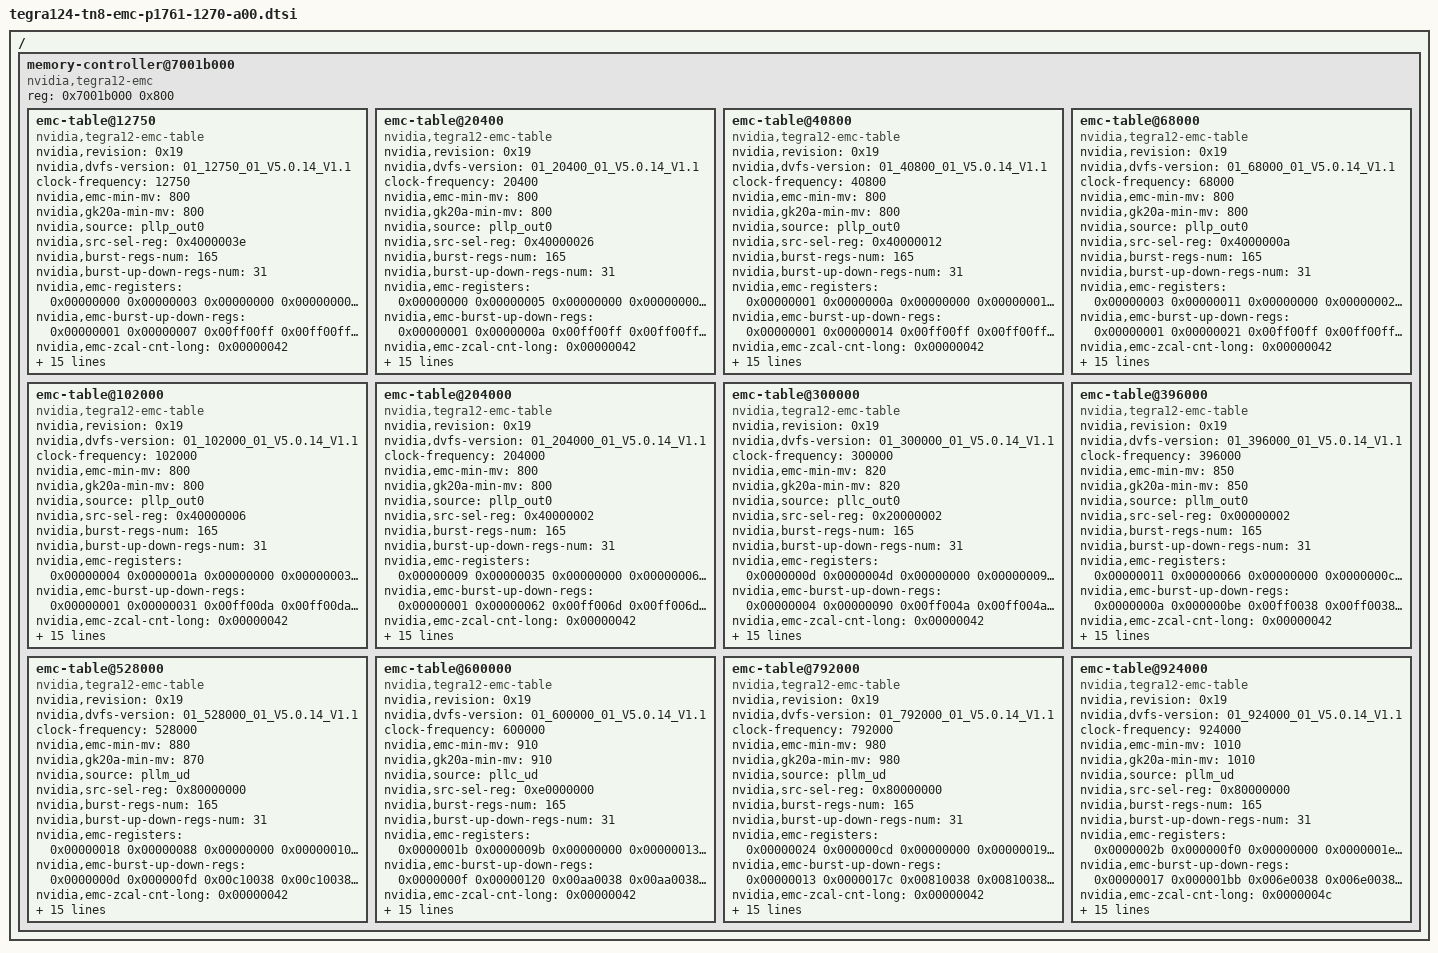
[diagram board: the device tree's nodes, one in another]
/ {
memory-controller@7001b000 {
		compatible = "nvidia,tegra12-emc";
		reg = <0x7001b000 0x800>;
		#address-cells = <1>;
		#size-cells = <0>;
		emc-table@12750 {
			compatible = "nvidia,tegra12-emc-table";
			nvidia,revision = <0x19>;
			nvidia,dvfs-version = "01_12750_01_V5.0.14_V1.1";
			clock-frequency = <12750>;
			nvidia,emc-min-mv = <800>;
			nvidia,gk20a-min-mv = <800>;
			nvidia,source = "pllp_out0";
			nvidia,src-sel-reg = <0x4000003e>;
			nvidia,burst-regs-num = <165>;
			nvidia,burst-up-down-regs-num = <31>;
			nvidia,emc-registers = <
				0x00000000
				0x00000003
				0x00000000
				0x00000000
				0x00000000
				0x00000004
				0x0000000a
				0x00000003
				0x0000000b
				0x00000000
				0x00000000
				0x00000003
				0x00000003
				0x00000000
				0x00000006
				0x00000006
				0x00000006
				0x00000002
				0x00000000
				0x00000005
				0x00000005
				0x00010000
				0x00000003
				0x00000000
				0x00000000
				0x00000000
				0x00000000
				0x00000004
				0x0000000c
				0x0000000d
				0x0000000f
				0x00000060
				0x00000000
				0x00000018
				0x00000002
				0x00000002
				0x00000001
				0x00000000
				0x00000007
				0x0000000f
				0x00000005
				0x00000005
				0x00000004
				0x00000005
				0x00000004
				0x00000000
				0x00000000
				0x00000005
				0x00000005
				0x00000064
				0x00000000
				0x00000000
				0x00000000
				0x1069a298
				0x002c00a0
				0x00008000
				0x00064000
				0x00064000
				0x00064000
				0x00064000
				0x00064000
				0x00064000
				0x00064000
				0x00064000
				0x00064000
				0x00064000
				0x00064000
				0x00064000
				0x00064000
				0x00064000
				0x00064000
				0x00064000
				0x00000000
				0x00000000
				0x00000000
				0x00000000
				0x00000000
				0x00000000
				0x00000000
				0x00000000
				0x00000000
				0x00000000
				0x00014000
				0x00000000
				0x00000000
				0x00014000
				0x00000000
				0x00000000
				0x00000000
				0x00000000
				0x00000000
				0x00000000
				0x00000000
				0x00000000
				0x00000000
				0x00000000
				0x00000000
				0x00000000
				0x00000000
				0x00000000
				0x00000000
				0x00000000
				0x00000000
				0x00000000
				0x00000000
				0x00000000
				0x00000000
				0x00000000
				0x00000000
				0x00000000
				0x000fc000
				0x000fc000
				0x000fc000
				0x000fc000
				0x0000fc00
				0x0000fc00
				0x0000fc00
				0x0000fc00
				0x10000280
				0x00000000
				0x00111111
				0x0130b118
				0x00000000
				0x00000000
				0x77ffc081
				0x00000909
				0x81f1f108
				0x07070004
				0x0000003f
				0x016eeeee
				0x51451400
				0x00514514
				0x00514514
				0x51451400
				0x0000003f
				0x00000007
				0x00000000
				0x00000000
				0x00000042
				0x000e000e
				0x000e000e
				0x00000000
				0x00000003
				0x0000f2f3
				0x800001c5
				0x0000000a
				0x40040001
				0x8000000a
				0x00000001
				0x00000001
				0x00000002
				0x00000000
				0x00000002
				0x00000001
				0x00000002
				0x00000008
				0x00000003
				0x00000002
				0x00000003
				0x00000006
				0x06030203
				0x000a0402
				0x77e30303
				0x70000f03
				0x001f0000
			>;
			nvidia,emc-burst-up-down-regs = <
			0x00000001
			0x00000007
			0x00ff00ff
			0x00ff00ff
			0x00ff00ff
			0x00ff00ff
			0x00ff00ff
			0x00ff00ff
			0x00ff00ff
			0x00ff0049
			0x00ff0080
			0x00ff0004
			0x00ff0004
			0x000800ff
			0x000000ff
			0x00ff0004
			0x00ff00ff
			0x00ff00ff
			0x00ff0024
			0x00ff00ff
			0x000000ff
			0x000000ff
			0x00ff00ff
			0x000000ff
			0x00ff00ff
			0x00ff00ff
			0x00ff00ff
			0x00ff00ff
			0x00ff00ff
			0x00ff00ff
			0x00ff00ff
			>;
			nvidia,emc-zcal-cnt-long = <0x00000042>;
			nvidia,emc-acal-interval = <0x001fffff>;
			nvidia,emc-ctt-term_ctrl = <0x00000802>;
			nvidia,emc-cfg = <0x73240000>;
			nvidia,emc-cfg-2 = <0x000008c5>;
			nvidia,emc-sel-dpd-ctrl = <0x00040128>;
			nvidia,emc-cfg-dig-dll = <0x002c0068>;
			nvidia,emc-bgbias-ctl0 = <0x00000008>;
			nvidia,emc-auto-cal-config2 = <0x00000000>;
			nvidia,emc-auto-cal-config3 = <0x00000000>;
			nvidia,emc-auto-cal-config = <0xa1430000>;
			nvidia,emc-mode-0 = <0x80001221>;
			nvidia,emc-mode-1 = <0x80100003>;
			nvidia,emc-mode-2 = <0x80200008>;
			nvidia,emc-mode-4 = <0x00000000>;
			nvidia,emc-clock-latency-change = <57820>;
		};
		emc-table@20400 {
			compatible = "nvidia,tegra12-emc-table";
			nvidia,revision = <0x19>;
			nvidia,dvfs-version = "01_20400_01_V5.0.14_V1.1";
			clock-frequency = <20400>;
			nvidia,emc-min-mv = <800>;
			nvidia,gk20a-min-mv = <800>;
			nvidia,source = "pllp_out0";
			nvidia,src-sel-reg = <0x40000026>;
			nvidia,burst-regs-num = <165>;
			nvidia,burst-up-down-regs-num = <31>;
			nvidia,emc-registers = <
				0x00000000
				0x00000005
				0x00000000
				0x00000000
				0x00000000
				0x00000004
				0x0000000a
				0x00000003
				0x0000000b
				0x00000000
				0x00000000
				0x00000003
				0x00000003
				0x00000000
				0x00000006
				0x00000006
				0x00000006
				0x00000002
				0x00000000
				0x00000005
				0x00000005
				0x00010000
				0x00000003
				0x00000000
				0x00000000
				0x00000000
				0x00000000
				0x00000004
				0x0000000c
				0x0000000d
				0x0000000f
				0x0000009a
				0x00000000
				0x00000026
				0x00000002
				0x00000002
				0x00000001
				0x00000000
				0x00000007
				0x0000000f
				0x00000006
				0x00000006
				0x00000004
				0x00000005
				0x00000004
				0x00000000
				0x00000000
				0x00000005
				0x00000005
				0x000000a0
				0x00000000
				0x00000000
				0x00000000
				0x1069a298
				0x002c00a0
				0x00008000
				0x00064000
				0x00064000
				0x00064000
				0x00064000
				0x00064000
				0x00064000
				0x00064000
				0x00064000
				0x00064000
				0x00064000
				0x00064000
				0x00064000
				0x00064000
				0x00064000
				0x00064000
				0x00064000
				0x00000000
				0x00000000
				0x00000000
				0x00000000
				0x00000000
				0x00000000
				0x00000000
				0x00000000
				0x00000000
				0x00000000
				0x00014000
				0x00000000
				0x00000000
				0x00014000
				0x00000000
				0x00000000
				0x00000000
				0x00000000
				0x00000000
				0x00000000
				0x00000000
				0x00000000
				0x00000000
				0x00000000
				0x00000000
				0x00000000
				0x00000000
				0x00000000
				0x00000000
				0x00000000
				0x00000000
				0x00000000
				0x00000000
				0x00000000
				0x00000000
				0x00000000
				0x00000000
				0x00000000
				0x000fc000
				0x000fc000
				0x000fc000
				0x000fc000
				0x0000fc00
				0x0000fc00
				0x0000fc00
				0x0000fc00
				0x10000280
				0x00000000
				0x00111111
				0x0130b118
				0x00000000
				0x00000000
				0x77ffc081
				0x00000909
				0x81f1f108
				0x07070004
				0x0000003f
				0x016eeeee
				0x51451400
				0x00514514
				0x00514514
				0x51451400
				0x0000003f
				0x0000000b
				0x00000000
				0x00000000
				0x00000042
				0x000e000e
				0x000e000e
				0x00000000
				0x00000003
				0x0000f2f3
				0x8000023a
				0x0000000a
				0x40020001
				0x80000012
				0x00000001
				0x00000001
				0x00000002
				0x00000000
				0x00000002
				0x00000001
				0x00000002
				0x00000008
				0x00000003
				0x00000002
				0x00000003
				0x00000006
				0x06030203
				0x000a0402
				0x76230303
				0x70000f03
				0x001f0000
			>;
			nvidia,emc-burst-up-down-regs = <
			0x00000001
			0x0000000a
			0x00ff00ff
			0x00ff00ff
			0x00ff00ff
			0x00ff00ff
			0x00ff00ff
			0x00ff00ff
			0x00ff00ff
			0x00ff0049
			0x00ff0080
			0x00ff0004
			0x00ff0004
			0x000800ff
			0x000000ff
			0x00ff0004
			0x00ff00ff
			0x00ff00ff
			0x00ff0024
			0x00ff00ff
			0x000000ff
			0x000000ff
			0x00ff00ff
			0x000000ff
			0x00ff00ff
			0x00ff00ff
			0x00ff00ff
			0x00ff00ff
			0x00ff00ff
			0x00ff00ff
			0x00ff00ff
			>;
			nvidia,emc-zcal-cnt-long = <0x00000042>;
			nvidia,emc-acal-interval = <0x001fffff>;
			nvidia,emc-ctt-term_ctrl = <0x00000802>;
			nvidia,emc-cfg = <0x73240000>;
			nvidia,emc-cfg-2 = <0x000008c5>;
			nvidia,emc-sel-dpd-ctrl = <0x00040128>;
			nvidia,emc-cfg-dig-dll = <0x002c0068>;
			nvidia,emc-bgbias-ctl0 = <0x00000008>;
			nvidia,emc-auto-cal-config2 = <0x00000000>;
			nvidia,emc-auto-cal-config3 = <0x00000000>;
			nvidia,emc-auto-cal-config = <0xa1430000>;
			nvidia,emc-mode-0 = <0x80001221>;
			nvidia,emc-mode-1 = <0x80100003>;
			nvidia,emc-mode-2 = <0x80200008>;
			nvidia,emc-mode-4 = <0x00000000>;
			nvidia,emc-clock-latency-change = <35610>;
		};
		emc-table@40800 {
			compatible = "nvidia,tegra12-emc-table";
			nvidia,revision = <0x19>;
			nvidia,dvfs-version = "01_40800_01_V5.0.14_V1.1";
			clock-frequency = <40800>;
			nvidia,emc-min-mv = <800>;
			nvidia,gk20a-min-mv = <800>;
			nvidia,source = "pllp_out0";
			nvidia,src-sel-reg = <0x40000012>;
			nvidia,burst-regs-num = <165>;
			nvidia,burst-up-down-regs-num = <31>;
			nvidia,emc-registers = <
				0x00000001
				0x0000000a
				0x00000000
				0x00000001
				0x00000000
				0x00000004
				0x0000000a
				0x00000003
				0x0000000b
				0x00000000
				0x00000000
				0x00000003
				0x00000003
				0x00000000
				0x00000006
				0x00000006
				0x00000006
				0x00000002
				0x00000000
				0x00000005
				0x00000005
				0x00010000
				0x00000003
				0x00000000
				0x00000000
				0x00000000
				0x00000000
				0x00000004
				0x0000000c
				0x0000000d
				0x0000000f
				0x00000134
				0x00000000
				0x0000004d
				0x00000002
				0x00000002
				0x00000001
				0x00000000
				0x00000008
				0x0000000f
				0x0000000c
				0x0000000c
				0x00000004
				0x00000005
				0x00000004
				0x00000000
				0x00000000
				0x00000005
				0x00000005
				0x0000013f
				0x00000000
				0x00000000
				0x00000000
				0x1069a298
				0x002c00a0
				0x00008000
				0x00064000
				0x00064000
				0x00064000
				0x00064000
				0x00064000
				0x00064000
				0x00064000
				0x00064000
				0x00064000
				0x00064000
				0x00064000
				0x00064000
				0x00064000
				0x00064000
				0x00064000
				0x00064000
				0x00000000
				0x00000000
				0x00000000
				0x00000000
				0x00000000
				0x00000000
				0x00000000
				0x00000000
				0x00000000
				0x00000000
				0x00014000
				0x00000000
				0x00000000
				0x00014000
				0x00000000
				0x00000000
				0x00000000
				0x00000000
				0x00000000
				0x00000000
				0x00000000
				0x00000000
				0x00000000
				0x00000000
				0x00000000
				0x00000000
				0x00000000
				0x00000000
				0x00000000
				0x00000000
				0x00000000
				0x00000000
				0x00000000
				0x00000000
				0x00000000
				0x00000000
				0x00000000
				0x00000000
				0x000fc000
				0x000fc000
				0x000fc000
				0x000fc000
				0x0000fc00
				0x0000fc00
				0x0000fc00
				0x0000fc00
				0x10000280
				0x00000000
				0x00111111
				0x0130b118
				0x00000000
				0x00000000
				0x77ffc081
				0x00000909
				0x81f1f108
				0x07070004
				0x0000003f
				0x016eeeee
				0x51451400
				0x00514514
				0x00514514
				0x51451400
				0x0000003f
				0x00000015
				0x00000000
				0x00000000
				0x00000042
				0x000e000e
				0x000e000e
				0x00000000
				0x00000003
				0x0000f2f3
				0x80000370
				0x0000000a
				0xa0000001
				0x80000017
				0x00000001
				0x00000001
				0x00000002
				0x00000000
				0x00000002
				0x00000001
				0x00000002
				0x00000008
				0x00000003
				0x00000002
				0x00000003
				0x00000006
				0x06030203
				0x000a0402
				0x74a30303
				0x70000f03
				0x001f0000
			>;
			nvidia,emc-burst-up-down-regs = <
			0x00000001
			0x00000014
			0x00ff00ff
			0x00ff00ff
			0x00ff00ff
			0x00ff00ff
			0x00ff00ff
			0x00ff00ff
			0x00ff00ff
			0x00ff0049
			0x00ff0080
			0x00ff0004
			0x00ff0004
			0x000800ff
			0x000000ff
			0x00ff0004
			0x00ff00ff
			0x00ff00ff
			0x00ff0024
			0x00ff00ff
			0x000000ff
			0x000000ff
			0x00ff00ff
			0x000000ff
			0x00ff00ff
			0x00ff00ff
			0x00ff00ff
			0x00ff00ff
			0x00ff00ff
			0x00ff00ff
			0x00ff00ff
			>;
			nvidia,emc-zcal-cnt-long = <0x00000042>;
			nvidia,emc-acal-interval = <0x001fffff>;
			nvidia,emc-ctt-term_ctrl = <0x00000802>;
			nvidia,emc-cfg = <0x73240000>;
			nvidia,emc-cfg-2 = <0x000008c5>;
			nvidia,emc-sel-dpd-ctrl = <0x00040128>;
			nvidia,emc-cfg-dig-dll = <0x002c0068>;
			nvidia,emc-bgbias-ctl0 = <0x00000008>;
			nvidia,emc-auto-cal-config2 = <0x00000000>;
			nvidia,emc-auto-cal-config3 = <0x00000000>;
			nvidia,emc-auto-cal-config = <0xa1430000>;
			nvidia,emc-mode-0 = <0x80001221>;
			nvidia,emc-mode-1 = <0x80100003>;
			nvidia,emc-mode-2 = <0x80200008>;
			nvidia,emc-mode-4 = <0x00000000>;
			nvidia,emc-clock-latency-change = <20850>;
		};
		emc-table@68000 {
			compatible = "nvidia,tegra12-emc-table";
			nvidia,revision = <0x19>;
			nvidia,dvfs-version = "01_68000_01_V5.0.14_V1.1";
			clock-frequency = <68000>;
			nvidia,emc-min-mv = <800>;
			nvidia,gk20a-min-mv = <800>;
			nvidia,source = "pllp_out0";
			nvidia,src-sel-reg = <0x4000000a>;
			nvidia,burst-regs-num = <165>;
			nvidia,burst-up-down-regs-num = <31>;
			nvidia,emc-registers = <
				0x00000003
				0x00000011
				0x00000000
				0x00000002
				0x00000000
				0x00000004
				0x0000000a
				0x00000003
				0x0000000b
				0x00000000
				0x00000000
				0x00000003
				0x00000003
				0x00000000
				0x00000006
				0x00000006
				0x00000006
				0x00000002
				0x00000000
				0x00000005
				0x00000005
				0x00010000
				0x00000003
				0x00000000
				0x00000000
				0x00000000
				0x00000000
				0x00000004
				0x0000000c
				0x0000000d
				0x0000000f
				0x00000202
				0x00000000
				0x00000080
				0x00000002
				0x00000002
				0x00000001
				0x00000000
				0x0000000f
				0x0000000f
				0x00000013
				0x00000013
				0x00000004
				0x00000005
				0x00000004
				0x00000001
				0x00000000
				0x00000005
				0x00000005
				0x00000213
				0x00000000
				0x00000000
				0x00000000
				0x1069a298
				0x002c00a0
				0x00008000
				0x00064000
				0x00064000
				0x00064000
				0x00064000
				0x00064000
				0x00064000
				0x00064000
				0x00064000
				0x00064000
				0x00064000
				0x00064000
				0x00064000
				0x00064000
				0x00064000
				0x00064000
				0x00064000
				0x00000000
				0x00000000
				0x00000000
				0x00000000
				0x00000000
				0x00000000
				0x00000000
				0x00000000
				0x00000000
				0x00000000
				0x00014000
				0x00000000
				0x00000000
				0x00014000
				0x00000000
				0x00000000
				0x00000000
				0x00000000
				0x00000000
				0x00000000
				0x00000000
				0x00000000
				0x00000000
				0x00000000
				0x00000000
				0x00000000
				0x00000000
				0x00000000
				0x00000000
				0x00000000
				0x00000000
				0x00000000
				0x00000000
				0x00000000
				0x00000000
				0x00000000
				0x00000000
				0x00000000
				0x000fc000
				0x000fc000
				0x000fc000
				0x000fc000
				0x0000fc00
				0x0000fc00
				0x0000fc00
				0x0000fc00
				0x10000280
				0x00000000
				0x00111111
				0x0130b118
				0x00000000
				0x00000000
				0x77ffc081
				0x00000909
				0x81f1f108
				0x07070004
				0x0000003f
				0x016eeeee
				0x51451400
				0x00514514
				0x00514514
				0x51451400
				0x0000003f
				0x00000022
				0x00000000
				0x00000000
				0x00000042
				0x000e000e
				0x000e000e
				0x00000000
				0x00000003
				0x0000f2f3
				0x8000050e
				0x0000000a
				0x00000001
				0x8000001e
				0x00000001
				0x00000001
				0x00000002
				0x00000000
				0x00000002
				0x00000001
				0x00000002
				0x00000008
				0x00000003
				0x00000002
				0x00000003
				0x00000006
				0x06030203
				0x000a0402
				0x74230403
				0x70000f03
				0x001f0000
			>;
			nvidia,emc-burst-up-down-regs = <
			0x00000001
			0x00000021
			0x00ff00ff
			0x00ff00ff
			0x00ff00b0
			0x00ff00ff
			0x00ff00ec
			0x00ff00ff
			0x00ff00ec
			0x00e90049
			0x00ff0080
			0x00ff0004
			0x00ff0004
			0x000800ff
			0x000000ff
			0x00ff0004
			0x00ff00ff
			0x00ff00a3
			0x00ff0024
			0x00ff00ff
			0x000000ff
			0x000000ef
			0x00ff00ff
			0x000000ef
			0x00ff00ff
			0x00ff00ff
			0x00ee00ef
			0x00ff00ff
			0x00ff00ff
			0x00ff00ff
			0x00ff00ff
			>;
			nvidia,emc-zcal-cnt-long = <0x00000042>;
			nvidia,emc-acal-interval = <0x001fffff>;
			nvidia,emc-ctt-term_ctrl = <0x00000802>;
			nvidia,emc-cfg = <0x73240000>;
			nvidia,emc-cfg-2 = <0x000008c5>;
			nvidia,emc-sel-dpd-ctrl = <0x00040128>;
			nvidia,emc-cfg-dig-dll = <0x002c0068>;
			nvidia,emc-bgbias-ctl0 = <0x00000008>;
			nvidia,emc-auto-cal-config2 = <0x00000000>;
			nvidia,emc-auto-cal-config3 = <0x00000000>;
			nvidia,emc-auto-cal-config = <0xa1430000>;
			nvidia,emc-mode-0 = <0x80001221>;
			nvidia,emc-mode-1 = <0x80100003>;
			nvidia,emc-mode-2 = <0x80200008>;
			nvidia,emc-mode-4 = <0x00000000>;
			nvidia,emc-clock-latency-change = <10720>;
		};
		emc-table@102000 {
			compatible = "nvidia,tegra12-emc-table";
			nvidia,revision = <0x19>;
			nvidia,dvfs-version = "01_102000_01_V5.0.14_V1.1";
			clock-frequency = <102000>;
			nvidia,emc-min-mv = <800>;
			nvidia,gk20a-min-mv = <800>;
			nvidia,source = "pllp_out0";
			nvidia,src-sel-reg = <0x40000006>;
			nvidia,burst-regs-num = <165>;
			nvidia,burst-up-down-regs-num = <31>;
			nvidia,emc-registers = <
				0x00000004
				0x0000001a
				0x00000000
				0x00000003
				0x00000001
				0x00000004
				0x0000000a
				0x00000003
				0x0000000b
				0x00000001
				0x00000001
				0x00000003
				0x00000003
				0x00000000
				0x00000006
				0x00000006
				0x00000006
				0x00000002
				0x00000000
				0x00000005
				0x00000005
				0x00010000
				0x00000003
				0x00000000
				0x00000000
				0x00000000
				0x00000000
				0x00000004
				0x0000000c
				0x0000000d
				0x0000000f
				0x00000304
				0x00000000
				0x000000c1
				0x00000002
				0x00000002
				0x00000001
				0x00000000
				0x00000018
				0x0000000f
				0x0000001c
				0x0000001c
				0x00000004
				0x00000005
				0x00000004
				0x00000002
				0x00000000
				0x00000005
				0x00000005
				0x0000031c
				0x00000000
				0x00000000
				0x00000000
				0x1069a298
				0x002c00a0
				0x00008000
				0x00064000
				0x00064000
				0x00064000
				0x00064000
				0x00064000
				0x00064000
				0x00064000
				0x00064000
				0x00064000
				0x00064000
				0x00064000
				0x00064000
				0x00064000
				0x00064000
				0x00064000
				0x00064000
				0x00000000
				0x00000000
				0x00000000
				0x00000000
				0x00000000
				0x00000000
				0x00000000
				0x00000000
				0x00000000
				0x00000000
				0x00014000
				0x00000000
				0x00000000
				0x00014000
				0x00000000
				0x00000000
				0x00000000
				0x00000000
				0x00000000
				0x00000000
				0x00000000
				0x00000000
				0x00000000
				0x00000000
				0x00000000
				0x00000000
				0x00000000
				0x00000000
				0x00000000
				0x00000000
				0x00000000
				0x00000000
				0x00000000
				0x00000000
				0x00000000
				0x00000000
				0x00000000
				0x00000000
				0x000fc000
				0x000fc000
				0x000fc000
				0x000fc000
				0x0000fc00
				0x0000fc00
				0x0000fc00
				0x0000fc00
				0x10000280
				0x00000000
				0x00111111
				0x0130b118
				0x00000000
				0x00000000
				0x77ffc081
				0x00000909
				0x81f1f108
				0x07070004
				0x0000003f
				0x016eeeee
				0x51451400
				0x00514514
				0x00514514
				0x51451400
				0x0000003f
				0x00000033
				0x00000000
				0x00000000
				0x00000042
				0x000e000e
				0x000e000e
				0x00000000
				0x00000003
				0x0000f2f3
				0x80000713
				0x0000000a
				0x08000001
				0x80000026
				0x00000001
				0x00000001
				0x00000003
				0x00000000
				0x00000002
				0x00000001
				0x00000002
				0x00000008
				0x00000003
				0x00000002
				0x00000003
				0x00000006
				0x06030203
				0x000a0403
				0x73c30504
				0x70000f03
				0x001f0000
			>;
			nvidia,emc-burst-up-down-regs = <
			0x00000001
			0x00000031
			0x00ff00da
			0x00ff00da
			0x00ff0075
			0x00ff00ff
			0x00ff009d
			0x00ff00ff
			0x00ff009d
			0x009b0049
			0x00ff0080
			0x00ff0004
			0x00ff0004
			0x000800ad
			0x000000ff
			0x00ff0004
			0x00ff00c6
			0x00ff006d
			0x00ff0024
			0x00ff00d6
			0x000000ff
			0x0000009f
			0x00ff00ff
			0x0000009f
			0x00ff00ff
			0x00ff00ff
			0x009f00a0
			0x00ff00ff
			0x00ff00ff
			0x00ff00ff
			0x00ff00da
			>;
			nvidia,emc-zcal-cnt-long = <0x00000042>;
			nvidia,emc-acal-interval = <0x001fffff>;
			nvidia,emc-ctt-term_ctrl = <0x00000802>;
			nvidia,emc-cfg = <0x73240000>;
			nvidia,emc-cfg-2 = <0x000008c5>;
			nvidia,emc-sel-dpd-ctrl = <0x00040128>;
			nvidia,emc-cfg-dig-dll = <0x002c0068>;
			nvidia,emc-bgbias-ctl0 = <0x00000008>;
			nvidia,emc-auto-cal-config2 = <0x00000000>;
			nvidia,emc-auto-cal-config3 = <0x00000000>;
			nvidia,emc-auto-cal-config = <0xa1430000>;
			nvidia,emc-mode-0 = <0x80001221>;
			nvidia,emc-mode-1 = <0x80100003>;
			nvidia,emc-mode-2 = <0x80200008>;
			nvidia,emc-mode-4 = <0x00000000>;
			nvidia,emc-clock-latency-change = <6890>;
		};
		emc-table@204000 {
			compatible = "nvidia,tegra12-emc-table";
			nvidia,revision = <0x19>;
			nvidia,dvfs-version = "01_204000_01_V5.0.14_V1.1";
			clock-frequency = <204000>;
			nvidia,emc-min-mv = <800>;
			nvidia,gk20a-min-mv = <800>;
			nvidia,source = "pllp_out0";
			nvidia,src-sel-reg = <0x40000002>;
			nvidia,burst-regs-num = <165>;
			nvidia,burst-up-down-regs-num = <31>;
			nvidia,emc-registers = <
				0x00000009
				0x00000035
				0x00000000
				0x00000006
				0x00000002
				0x00000005
				0x0000000a
				0x00000003
				0x0000000b
				0x00000002
				0x00000002
				0x00000003
				0x00000003
				0x00000000
				0x00000005
				0x00000005
				0x00000006
				0x00000002
				0x00000000
				0x00000004
				0x00000006
				0x00010000
				0x00000003
				0x00000000
				0x00000000
				0x00000000
				0x00000000
				0x00000003
				0x0000000d
				0x0000000f
				0x00000011
				0x00000607
				0x00000000
				0x00000181
				0x00000002
				0x00000002
				0x00000001
				0x00000000
				0x00000032
				0x0000000f
				0x00000038
				0x00000038
				0x00000004
				0x00000005
				0x00000004
				0x00000006
				0x00000000
				0x00000005
				0x00000005
				0x00000638
				0x00000000
				0x00000000
				0x00000000
				0x1069a298
				0x002c00a0
				0x00008000
				0x00064000
				0x00064000
				0x00064000
				0x00064000
				0x00064000
				0x00064000
				0x00064000
				0x00064000
				0x00064000
				0x00064000
				0x00064000
				0x00064000
				0x00064000
				0x00064000
				0x00064000
				0x00064000
				0x00000000
				0x00000000
				0x00000000
				0x00000000
				0x00000000
				0x00000000
				0x00000000
				0x00000000
				0x00000000
				0x00000000
				0x00014000
				0x00000000
				0x00000000
				0x00014000
				0x00000000
				0x00000000
				0x00000000
				0x00000000
				0x00000000
				0x00000000
				0x00000000
				0x00000000
				0x00000000
				0x00000000
				0x00000000
				0x00000000
				0x00000000
				0x00000000
				0x00000000
				0x00000000
				0x00000000
				0x00000000
				0x00000000
				0x00000000
				0x00000000
				0x00000000
				0x00000000
				0x00000000
				0x00078000
				0x00078000
				0x00078000
				0x00078000
				0x00007800
				0x00007800
				0x00007800
				0x00007800
				0x10000280
				0x00000000
				0x00111111
				0x0130b118
				0x00000000
				0x00000000
				0x77ffc081
				0x00000909
				0x81f1f108
				0x07070004
				0x0000003f
				0x016eeeee
				0x51451400
				0x00514514
				0x00514514
				0x51451400
				0x0000003f
				0x00000066
				0x00000000
				0x00020000
				0x00000100
				0x000e000e
				0x000e000e
				0x00000000
				0x00000003
				0x0000d2b3
				0x80000d22
				0x0000000a
				0x01000003
				0x80000040
				0x00000001
				0x00000001
				0x00000004
				0x00000002
				0x00000003
				0x00000001
				0x00000002
				0x00000008
				0x00000003
				0x00000002
				0x00000004
				0x00000006
				0x06040203
				0x000a0404
				0x73840a05
				0x70000f03
				0x001f0000
			>;
			nvidia,emc-burst-up-down-regs = <
			0x00000001
			0x00000062
			0x00ff006d
			0x00ff006d
			0x00ff003c
			0x00ff00af
			0x00ff004f
			0x00ff00af
			0x00ff004f
			0x004e0049
			0x00ff0080
			0x00ff0004
			0x00ff0004
			0x00080057
			0x000000ff
			0x00ff0004
			0x00ff0063
			0x00ff0036
			0x00ff0024
			0x00ff006b
			0x000000ff
			0x00000050
			0x00ff00ff
			0x00000050
			0x00ff00ff
			0x00d400ff
			0x00510050
			0x00ff00ff
			0x00ff00ff
			0x00ff00c6
			0x00ff006d
			>;
			nvidia,emc-zcal-cnt-long = <0x00000042>;
			nvidia,emc-acal-interval = <0x001fffff>;
			nvidia,emc-ctt-term_ctrl = <0x00000802>;
			nvidia,emc-cfg = <0x73240000>;
			nvidia,emc-cfg-2 = <0x000008cd>;
			nvidia,emc-sel-dpd-ctrl = <0x00040128>;
			nvidia,emc-cfg-dig-dll = <0x002c0068>;
			nvidia,emc-bgbias-ctl0 = <0x00000008>;
			nvidia,emc-auto-cal-config2 = <0x00000000>;
			nvidia,emc-auto-cal-config3 = <0x00000000>;
			nvidia,emc-auto-cal-config = <0xa1430000>;
			nvidia,emc-mode-0 = <0x80001221>;
			nvidia,emc-mode-1 = <0x80100003>;
			nvidia,emc-mode-2 = <0x80200008>;
			nvidia,emc-mode-4 = <0x00000000>;
			nvidia,emc-clock-latency-change = <3420>;
		};
		emc-table@300000 {
			compatible = "nvidia,tegra12-emc-table";
			nvidia,revision = <0x19>;
			nvidia,dvfs-version = "01_300000_01_V5.0.14_V1.1";
			clock-frequency = <300000>;
			nvidia,emc-min-mv = <820>;
			nvidia,gk20a-min-mv = <820>;
			nvidia,source = "pllc_out0";
			nvidia,src-sel-reg = <0x20000002>;
			nvidia,burst-regs-num = <165>;
			nvidia,burst-up-down-regs-num = <31>;
			nvidia,emc-registers = <
				0x0000000d
				0x0000004d
				0x00000000
				0x00000009
				0x00000003
				0x00000004
				0x00000008
				0x00000002
				0x00000009
				0x00000003
				0x00000003
				0x00000002
				0x00000002
				0x00000000
				0x00000003
				0x00000003
				0x00000005
				0x00000002
				0x00000000
				0x00000002
				0x00000007
				0x00020000
				0x00000003
				0x00000000
				0x00000000
				0x00000000
				0x00000000
				0x00000001
				0x0000000e
				0x00000010
				0x00000012
				0x000008e4
				0x00000000
				0x00000239
				0x00000001
				0x00000008
				0x00000001
				0x00000000
				0x0000004b
				0x0000000e
				0x00000052
				0x00000200
				0x00000004
				0x00000005
				0x00000004
				0x00000008
				0x00000000
				0x00000005
				0x00000005
				0x00000924
				0x00000000
				0x00000000
				0x00000000
				0x1049b098
				0x002c00a0
				0x00008000
				0x00070000
				0x00070000
				0x00070000
				0x00070000
				0x00070000
				0x00070000
				0x00070000
				0x00070000
				0x00070000
				0x00070000
				0x00070000
				0x00070000
				0x00070000
				0x00070000
				0x00070000
				0x00070000
				0x00000000
				0x00000000
				0x00000000
				0x00000000
				0x00000000
				0x00000000
				0x00000000
				0x00000000
				0x0008c000
				0x0008c000
				0x00000000
				0x0008c000
				0x0008c000
				0x00000000
				0x00000000
				0x00000000
				0x00000000
				0x00000000
				0x00000000
				0x00000000
				0x00000000
				0x00000000
				0x00000000
				0x00000000
				0x00000000
				0x00000000
				0x00000000
				0x00000000
				0x00000000
				0x00000000
				0x00000000
				0x00000000
				0x00000000
				0x00000000
				0x00000000
				0x00000000
				0x00000000
				0x00000000
				0x00050000
				0x00050000
				0x00050000
				0x00050000
				0x00005000
				0x00005000
				0x00005000
				0x00005000
				0x10000280
				0x00000000
				0x00111111
				0x01231339
				0x00000000
				0x00000000
				0x77ffc081
				0x00000303
				0x81f1f108
				0x07070004
				0x00000000
				0x016eeeee
				0x51451420
				0x00514514
				0x00514514
				0x51451400
				0x0000003f
				0x00000096
				0x00000000
				0x00020000
				0x00000100
				0x0173000e
				0x0173000e
				0x00000000
				0x00000003
				0x000052a3
				0x800012d7
				0x00000009
				0x08000004
				0x80000040
				0x00000001
				0x00000002
				0x00000007
				0x00000004
				0x00000004
				0x00000001
				0x00000002
				0x00000007
				0x00000002
				0x00000002
				0x00000004
				0x00000006
				0x06040202
				0x000b0607
				0x77450e08
				0x70000f03
				0x001f0000
			>;
			nvidia,emc-burst-up-down-regs = <
			0x00000004
			0x00000090
			0x00ff004a
			0x00ff004a
			0x00ff003c
			0x00ff0090
			0x00ff0041
			0x00ff0090
			0x00ff0041
			0x00350049
			0x00ff0080
			0x00ff0004
			0x00ff0004
			0x0008003b
			0x000000ff
			0x00ff0004
			0x00ff0043
			0x00ff002d
			0x00ff0024
			0x00ff0049
			0x000000ff
			0x00000036
			0x00ff00ff
			0x00000036
			0x00ff00ff
			0x00d400ff
			0x00510036
			0x00ff00ff
			0x00ff00ff
			0x00ff0087
			0x00ff004a
			>;
			nvidia,emc-zcal-cnt-long = <0x00000042>;
			nvidia,emc-acal-interval = <0x001fffff>;
			nvidia,emc-ctt-term_ctrl = <0x00000802>;
			nvidia,emc-cfg = <0x73340000>;
			nvidia,emc-cfg-2 = <0x000008d5>;
			nvidia,emc-sel-dpd-ctrl = <0x00040128>;
			nvidia,emc-cfg-dig-dll = <0x002c0068>;
			nvidia,emc-bgbias-ctl0 = <0x00000000>;
			nvidia,emc-auto-cal-config2 = <0x00000000>;
			nvidia,emc-auto-cal-config3 = <0x00000000>;
			nvidia,emc-auto-cal-config = <0xa1430000>;
			nvidia,emc-mode-0 = <0x80000321>;
			nvidia,emc-mode-1 = <0x80100002>;
			nvidia,emc-mode-2 = <0x80200000>;
			nvidia,emc-mode-4 = <0x00000000>;
			nvidia,emc-clock-latency-change = <2680>;
		};
		emc-table@396000 {
			compatible = "nvidia,tegra12-emc-table";
			nvidia,revision = <0x19>;
			nvidia,dvfs-version = "01_396000_01_V5.0.14_V1.1";
			clock-frequency = <396000>;
			nvidia,emc-min-mv = <850>;
			nvidia,gk20a-min-mv = <850>;
			nvidia,source = "pllm_out0";
			nvidia,src-sel-reg = <0x00000002>;
			nvidia,burst-regs-num = <165>;
			nvidia,burst-up-down-regs-num = <31>;
			nvidia,emc-registers = <
				0x00000011
				0x00000066
				0x00000000
				0x0000000c
				0x00000004
				0x00000004
				0x00000008
				0x00000002
				0x0000000a
				0x00000004
				0x00000004
				0x00000002
				0x00000002
				0x00000000
				0x00000003
				0x00000003
				0x00000005
				0x00000002
				0x00000000
				0x00000001
				0x00000008
				0x00020000
				0x00000003
				0x00000000
				0x00000000
				0x00000000
				0x00000000
				0x00000000
				0x0000000f
				0x00000010
				0x00000012
				0x00000bd1
				0x00000000
				0x000002f4
				0x00000001
				0x00000008
				0x00000001
				0x00000000
				0x00000063
				0x0000000f
				0x0000006c
				0x00000200
				0x00000004
				0x00000005
				0x00000004
				0x0000000b
				0x00000000
				0x00000005
				0x00000005
				0x00000c11
				0x00000000
				0x00000000
				0x00000000
				0x1049b098
				0x002c00a0
				0x00008000
				0x00070000
				0x00070000
				0x00070000
				0x00070000
				0x00070000
				0x00070000
				0x00070000
				0x00070000
				0x00070000
				0x00070000
				0x00070000
				0x00070000
				0x00070000
				0x00070000
				0x00070000
				0x00070000
				0x00000000
				0x00000000
				0x00000000
				0x00000000
				0x00000000
				0x00000000
				0x00000000
				0x00000000
				0x00064000
				0x00064000
				0x00000000
				0x00064000
				0x00064000
				0x00000000
				0x00000000
				0x00000000
				0x00000000
				0x00000000
				0x00000000
				0x00000000
				0x00000000
				0x00000000
				0x00000000
				0x00000000
				0x00000000
				0x00000000
				0x00000000
				0x00000000
				0x00000000
				0x00000000
				0x00000000
				0x00000000
				0x00000000
				0x00000000
				0x00000000
				0x00000000
				0x00000000
				0x00000000
				0x00040000
				0x00040000
				0x00040000
				0x00040000
				0x00004000
				0x00004000
				0x00004000
				0x00004000
				0x10000280
				0x00000000
				0x00111111
				0x01231339
				0x00000000
				0x00000000
				0x77ffc081
				0x00000303
				0x81f1f108
				0x07070004
				0x00000000
				0x016eeeee
				0x51451420
				0x00514514
				0x00514514
				0x51451400
				0x0000003f
				0x000000c6
				0x00000000
				0x00020000
				0x00000100
				0x015b000e
				0x015b000e
				0x00000000
				0x00000003
				0x000052a3
				0x8000188b
				0x00000009
				0x0f000005
				0x80000040
				0x00000001
				0x00000002
				0x00000009
				0x00000005
				0x00000006
				0x00000001
				0x00000002
				0x00000008
				0x00000002
				0x00000002
				0x00000004
				0x00000006
				0x06040202
				0x000d0709
				0x7586120a
				0x70000f03
				0x001f0000
			>;
			nvidia,emc-burst-up-down-regs = <
			0x0000000a
			0x000000be
			0x00ff0038
			0x00ff0038
			0x00ff003c
			0x00ff0090
			0x00ff0041
			0x00ff0090
			0x00ff0041
			0x00280049
			0x00ff0080
			0x00ff0004
			0x00ff0004
			0x0008002d
			0x000000ff
			0x00ff0004
			0x00ff0033
			0x00ff0022
			0x00ff0024
			0x00ff0037
			0x000000ff
			0x00000036
			0x00ff00ff
			0x00000036
			0x00ff00ff
			0x00d400ff
			0x00510029
			0x00ff00ff
			0x00ff00ff
			0x00ff0066
			0x00ff0038
			>;
			nvidia,emc-zcal-cnt-long = <0x00000042>;
			nvidia,emc-acal-interval = <0x001fffff>;
			nvidia,emc-ctt-term_ctrl = <0x00000802>;
			nvidia,emc-cfg = <0x73340000>;
			nvidia,emc-cfg-2 = <0x00000895>;
			nvidia,emc-sel-dpd-ctrl = <0x00040008>;
			nvidia,emc-cfg-dig-dll = <0x002c0068>;
			nvidia,emc-bgbias-ctl0 = <0x00000000>;
			nvidia,emc-auto-cal-config2 = <0x00000000>;
			nvidia,emc-auto-cal-config3 = <0x00000000>;
			nvidia,emc-auto-cal-config = <0xa1430000>;
			nvidia,emc-mode-0 = <0x80000521>;
			nvidia,emc-mode-1 = <0x80100002>;
			nvidia,emc-mode-2 = <0x80200000>;
			nvidia,emc-mode-4 = <0x00000000>;
			nvidia,emc-clock-latency-change = <2180>;
		};
		emc-table@528000 {
			compatible = "nvidia,tegra12-emc-table";
			nvidia,revision = <0x19>;
			nvidia,dvfs-version = "01_528000_01_V5.0.14_V1.1";
			clock-frequency = <528000>;
			nvidia,emc-min-mv = <880>;
			nvidia,gk20a-min-mv = <870>;
			nvidia,source = "pllm_ud";
			nvidia,src-sel-reg = <0x80000000>;
			nvidia,burst-regs-num = <165>;
			nvidia,burst-up-down-regs-num = <31>;
			nvidia,emc-registers = <
				0x00000018
				0x00000088
				0x00000000
				0x00000010
				0x00000006
				0x00000006
				0x00000009
				0x00000002
				0x0000000d
				0x00000006
				0x00000006
				0x00000002
				0x00000002
				0x00000000
				0x00000003
				0x00000003
				0x00000006
				0x00000002
				0x00000000
				0x00000001
				0x00000009
				0x00030000
				0x00000003
				0x00000000
				0x00000000
				0x00000000
				0x00000000
				0x00000000
				0x00000010
				0x00000012
				0x00000014
				0x00000fd6
				0x00000000
				0x000003f5
				0x00000002
				0x0000000b
				0x00000001
				0x00000000
				0x00000085
				0x00000012
				0x00000090
				0x00000200
				0x00000004
				0x00000005
				0x00000004
				0x00000010
				0x00000000
				0x00000006
				0x00000006
				0x00001017
				0x00000000
				0x00000000
				0x00000000
				0x1049b098
				0xe01200b1
				0x00008000
				0x0000000a
				0x0000000a
				0x0000000a
				0x0000000a
				0x0000000a
				0x0000000a
				0x0000000a
				0x0000000a
				0x0000000a
				0x0000000a
				0x0000000a
				0x0000000a
				0x0000000a
				0x0000000a
				0x0000000a
				0x0000000a
				0x00000000
				0x00000000
				0x00000000
				0x00000000
				0x00000000
				0x00000000
				0x00000000
				0x00000000
				0x00044000
				0x00044000
				0x00000000
				0x00044000
				0x00044000
				0x00000000
				0x00000000
				0x00000000
				0x00000000
				0x00000000
				0x00000000
				0x00000000
				0x00000000
				0x00000000
				0x00000002
				0x00000002
				0x00000002
				0x00000002
				0x00000004
				0x00000004
				0x00000004
				0x00000004
				0x00000002
				0x00000002
				0x00000002
				0x00000002
				0x00000004
				0x00000004
				0x00000004
				0x00000004
				0x0000000e
				0x0000000e
				0x0000000e
				0x0000000e
				0x0000000e
				0x0000000e
				0x0000000e
				0x0000000e
				0x100002a0
				0x00000000
				0x00111111
				0x0123133d
				0x00000000
				0x00000000
				0x77ffc085
				0x00000303
				0x81f1f108
				0x07070004
				0x00000000
				0x016eeeee
				0x51451420
				0x00514514
				0x00514514
				0x51451400
				0x0606003f
				0x00000000
				0x00000000
				0x00020000
				0x00000100
				0x0139000e
				0x0139000e
				0x00000000
				0x00000003
				0x000042a0
				0x80002062
				0x0000000a
				0x0f000007
				0x80000040
				0x00000002
				0x00000003
				0x0000000c
				0x00000007
				0x00000008
				0x00000001
				0x00000002
				0x00000009
				0x00000002
				0x00000002
				0x00000005
				0x00000006
				0x06050202
				0x0010090c
				0x7428180d
				0x70000f03
				0x001f0000
			>;
			nvidia,emc-burst-up-down-regs = <
			0x0000000d
			0x000000fd
			0x00c10038
			0x00c10038
			0x00c1003c
			0x00c10090
			0x00c10041
			0x00c10090
			0x00c10041
			0x00270049
			0x00c10080
			0x00c10004
			0x00c10004
			0x00080021
			0x000000c1
			0x00c10004
			0x00c10026
			0x00c1001a
			0x00c10024
			0x00c10029
			0x000000c1
			0x00000036
			0x00c100c1
			0x00000036
			0x00c100c1
			0x00d400ff
			0x00510029
			0x00c100c1
			0x00c100c1
			0x00c10065
			0x00c1002a
			>;
			nvidia,emc-zcal-cnt-long = <0x00000042>;
			nvidia,emc-acal-interval = <0x001fffff>;
			nvidia,emc-ctt-term_ctrl = <0x00000802>;
			nvidia,emc-cfg = <0x73300000>;
			nvidia,emc-cfg-2 = <0x0000089d>;
			nvidia,emc-sel-dpd-ctrl = <0x00040008>;
			nvidia,emc-cfg-dig-dll = <0xe0120069>;
			nvidia,emc-bgbias-ctl0 = <0x00000000>;
			nvidia,emc-auto-cal-config2 = <0x00000000>;
			nvidia,emc-auto-cal-config3 = <0x00000000>;
			nvidia,emc-auto-cal-config = <0xa1430000>;
			nvidia,emc-mode-0 = <0x80000941>;
			nvidia,emc-mode-1 = <0x80100002>;
			nvidia,emc-mode-2 = <0x80200008>;
			nvidia,emc-mode-4 = <0x00000000>;
			nvidia,emc-clock-latency-change = <1440>;
		};
		emc-table@600000 {
			compatible = "nvidia,tegra12-emc-table";
			nvidia,revision = <0x19>;
			nvidia,dvfs-version = "01_600000_01_V5.0.14_V1.1";
			clock-frequency = <600000>;
			nvidia,emc-min-mv = <910>;
			nvidia,gk20a-min-mv = <910>;
			nvidia,source = "pllc_ud";
			nvidia,src-sel-reg = <0xe0000000>;
			nvidia,burst-regs-num = <165>;
			nvidia,burst-up-down-regs-num = <31>;
			nvidia,emc-registers = <
				0x0000001b
				0x0000009b
				0x00000000
				0x00000013
				0x00000007
				0x00000007
				0x0000000b
				0x00000003
				0x00000010
				0x00000007
				0x00000007
				0x00000002
				0x00000002
				0x00000000
				0x00000005
				0x00000005
				0x0000000a
				0x00000002
				0x00000000
				0x00000003
				0x0000000b
				0x00070000
				0x00000003
				0x00000000
				0x00000000
				0x00000000
				0x00000000
				0x00000002
				0x00000012
				0x00000016
				0x00000018
				0x00001208
				0x00000000
				0x00000482
				0x00000002
				0x0000000d
				0x00000001
				0x00000000
				0x00000097
				0x00000015
				0x000000a3
				0x00000200
				0x00000004
				0x00000005
				0x00000004
				0x00000013
				0x00000000
				0x00000006
				0x00000006
				0x00001248
				0x00000000
				0x00000000
				0x00000000
				0x1049b098
				0xe00e00b1
				0x00008000
				0x0000000a
				0x0000000a
				0x0000000a
				0x0000000a
				0x0000000a
				0x0000000a
				0x0000000a
				0x0000000a
				0x0000000a
				0x0000000a
				0x0000000a
				0x0000000a
				0x0000000a
				0x0000000a
				0x0000000a
				0x0000000a
				0x00000000
				0x00000000
				0x00000000
				0x00000000
				0x00000000
				0x00000000
				0x00000000
				0x00000000
				0x0003c000
				0x0003c000
				0x00000000
				0x0003c000
				0x0003c000
				0x00000000
				0x00000000
				0x00000000
				0x00000000
				0x00000000
				0x00000000
				0x00000000
				0x00000000
				0x00000000
				0x00000004
				0x00000004
				0x00000004
				0x00000004
				0x00000006
				0x00000006
				0x00000006
				0x00000006
				0x00000004
				0x00000004
				0x00000004
				0x00000004
				0x00000006
				0x00000006
				0x00000006
				0x00000006
				0x0000000c
				0x0000000c
				0x0000000c
				0x0000000c
				0x0000000c
				0x0000000c
				0x0000000c
				0x0000000c
				0x100002a0
				0x00000000
				0x00111111
				0x0121113d
				0x00000000
				0x00000000
				0x77ffc085
				0x00000303
				0x81f1f108
				0x07070004
				0x00000000
				0x016eeeee
				0x51451420
				0x00514514
				0x00514514
				0x51451400
				0x0606003f
				0x00000000
				0x00000000
				0x00020000
				0x00000100
				0x0127000e
				0x0127000e
				0x00000000
				0x00000003
				0x000040a0
				0x800024aa
				0x0000000e
				0x00000009
				0x80000040
				0x00000003
				0x00000004
				0x0000000e
				0x00000009
				0x0000000a
				0x00000001
				0x00000003
				0x0000000b
				0x00000002
				0x00000002
				0x00000005
				0x00000007
				0x07050202
				0x00130b0e
				0x73a91b0f
				0x70000f03
				0x001f0000
			>;
			nvidia,emc-burst-up-down-regs = <
			0x0000000f
			0x00000120
			0x00aa0038
			0x00aa0038
			0x00aa003c
			0x00aa0090
			0x00aa0041
			0x00aa0090
			0x00aa0041
			0x00270049
			0x00aa0080
			0x00aa0004
			0x00aa0004
			0x0008001d
			0x000000aa
			0x00aa0004
			0x00aa0022
			0x00aa0018
			0x00aa0024
			0x00aa0024
			0x000000aa
			0x00000036
			0x00aa00aa
			0x00000036
			0x00aa00aa
			0x00d400ff
			0x00510029
			0x00aa00aa
			0x00aa00aa
			0x00aa0065
			0x00aa0025
			>;
			nvidia,emc-zcal-cnt-long = <0x00000042>;
			nvidia,emc-acal-interval = <0x001fffff>;
			nvidia,emc-ctt-term_ctrl = <0x00000802>;
			nvidia,emc-cfg = <0x73300000>;
			nvidia,emc-cfg-2 = <0x0000089d>;
			nvidia,emc-sel-dpd-ctrl = <0x00040008>;
			nvidia,emc-cfg-dig-dll = <0xe00e0069>;
			nvidia,emc-bgbias-ctl0 = <0x00000000>;
			nvidia,emc-auto-cal-config2 = <0x00000000>;
			nvidia,emc-auto-cal-config3 = <0x00000000>;
			nvidia,emc-auto-cal-config = <0xa1430000>;
			nvidia,emc-mode-0 = <0x80000b61>;
			nvidia,emc-mode-1 = <0x80100002>;
			nvidia,emc-mode-2 = <0x80200010>;
			nvidia,emc-mode-4 = <0x00000000>;
			nvidia,emc-clock-latency-change = <1440>;
		};
		emc-table@792000 {
			compatible = "nvidia,tegra12-emc-table";
			nvidia,revision = <0x19>;
			nvidia,dvfs-version = "01_792000_01_V5.0.14_V1.1";
			clock-frequency = <792000>;
			nvidia,emc-min-mv = <980>;
			nvidia,gk20a-min-mv = <980>;
			nvidia,source = "pllm_ud";
			nvidia,src-sel-reg = <0x80000000>;
			nvidia,burst-regs-num = <165>;
			nvidia,burst-up-down-regs-num = <31>;
			nvidia,emc-registers = <
				0x00000024
				0x000000cd
				0x00000000
				0x00000019
				0x0000000a
				0x00000008
				0x0000000d
				0x00000004
				0x00000013
				0x0000000a
				0x0000000a
				0x00000004
				0x00000002
				0x00000000
				0x00000006
				0x00000006
				0x0000000b
				0x00000002
				0x00000000
				0x00000002
				0x0000000d
				0x00080000
				0x00000004
				0x00000000
				0x00000000
				0x00000000
				0x00000000
				0x00000001
				0x00000014
				0x00000018
				0x0000001a
				0x000017e2
				0x00000000
				0x000005f8
				0x00000003
				0x00000011
				0x00000001
				0x00000000
				0x000000c7
				0x00000018
				0x000000d7
				0x00000200
				0x00000005
				0x00000006
				0x00000005
				0x00000019
				0x00000000
				0x00000008
				0x00000008
				0x00001822
				0x00000000
				0x00000000
				0x00000000
				0x1049b098
				0xe00700b1
				0x00008000
				0x00000007
				0x00000007
				0x00000007
				0x00000007
				0x00000007
				0x00000007
				0x00000007
				0x00000007
				0x00000007
				0x00000007
				0x00000007
				0x00000007
				0x00000007
				0x00000007
				0x00000007
				0x00000007
				0x00000000
				0x00000000
				0x00000000
				0x00000000
				0x00000000
				0x00000000
				0x00000000
				0x00000000
				0x00028000
				0x00028000
				0x00000000
				0x00028000
				0x00028000
				0x00000000
				0x00000000
				0x00000000
				0x00000000
				0x00000000
				0x00000000
				0x00000000
				0x00000000
				0x00000000
				0x00000007
				0x00000007
				0x00000007
				0x00000007
				0x0000000a
				0x0000000a
				0x0000000a
				0x0000000a
				0x00000007
				0x00000007
				0x00000007
				0x00000007
				0x0000000a
				0x0000000a
				0x0000000a
				0x0000000a
				0x0000000a
				0x0000000a
				0x0000000a
				0x0000000a
				0x0000000a
				0x0000000a
				0x0000000a
				0x0000000a
				0x100002a0
				0x00000000
				0x00111111
				0x0120113d
				0x00000000
				0x00000000
				0x77ffc085
				0x00000606
				0x81f1f108
				0x07070004
				0x00000000
				0x016eeeee
				0x61861820
				0x00555555
				0x00555555
				0x61861800
				0x0606003f
				0x00000000
				0x00000000
				0x00020000
				0x00000100
				0x00f7000e
				0x00f7000e
				0x00000000
				0x00000004
				0x00004080
				0x80003012
				0x0000000f
				0x0e00000b
				0x80000040
				0x00000004
				0x00000005
				0x00000013
				0x0000000c
				0x0000000d
				0x00000002
				0x00000003
				0x0000000c
				0x00000002
				0x00000002
				0x00000006
				0x00000008
				0x08060202
				0x00170e13
				0x736c2414
				0x70000f02
				0x001f0000
			>;
			nvidia,emc-burst-up-down-regs = <
			0x00000013
			0x0000017c
			0x00810038
			0x00810038
			0x0081003c
			0x00810090
			0x00810041
			0x00810090
			0x00810041
			0x00270049
			0x00810080
			0x00810004
			0x00810004
			0x00080016
			0x00000081
			0x00810004
			0x00810019
			0x00810018
			0x00810024
			0x0081001c
			0x00000081
			0x00000036
			0x00810081
			0x00000036
			0x00810081
			0x00d400ff
			0x00510029
			0x00810081
			0x00810081
			0x00810065
			0x0081001c
			>;
			nvidia,emc-zcal-cnt-long = <0x00000042>;
			nvidia,emc-acal-interval = <0x001fffff>;
			nvidia,emc-ctt-term_ctrl = <0x00000802>;
			nvidia,emc-cfg = <0x73300000>;
			nvidia,emc-cfg-2 = <0x0000089d>;
			nvidia,emc-sel-dpd-ctrl = <0x00040000>;
			nvidia,emc-cfg-dig-dll = <0xe0070069>;
			nvidia,emc-bgbias-ctl0 = <0x00000000>;
			nvidia,emc-auto-cal-config2 = <0x00000000>;
			nvidia,emc-auto-cal-config3 = <0x00000000>;
			nvidia,emc-auto-cal-config = <0xa1430000>;
			nvidia,emc-mode-0 = <0x80000d71>;
			nvidia,emc-mode-1 = <0x80100002>;
			nvidia,emc-mode-2 = <0x80200018>;
			nvidia,emc-mode-4 = <0x00000000>;
			nvidia,emc-clock-latency-change = <1200>;
		};
		emc-table@924000 {
			compatible = "nvidia,tegra12-emc-table";
			nvidia,revision = <0x19>;
			nvidia,dvfs-version = "01_924000_01_V5.0.14_V1.1";
			clock-frequency = <924000>;
			nvidia,emc-min-mv = <1010>;
			nvidia,gk20a-min-mv = <1010>;
			nvidia,source = "pllm_ud";
			nvidia,src-sel-reg = <0x80000000>;
			nvidia,burst-regs-num = <165>;
			nvidia,burst-up-down-regs-num = <31>;
			nvidia,emc-registers = <
				0x0000002b
				0x000000f0
				0x00000000
				0x0000001e
				0x0000000b
				0x00000009
				0x0000000f
				0x00000005
				0x00000016
				0x0000000b
				0x0000000b
				0x00000004
				0x00000002
				0x00000000
				0x00000007
				0x00000007
				0x0000000d
				0x00000002
				0x00000000
				0x00000002
				0x0000000f
				0x000a0000
				0x00000004
				0x00000000
				0x00000000
				0x00000000
				0x00000000
				0x00000001
				0x00000016
				0x0000001a
				0x0000001c
				0x00001be7
				0x00000000
				0x000006f9
				0x00000004
				0x00000015
				0x00000001
				0x00000000
				0x000000e7
				0x0000001b
				0x000000fb
				0x00000200
				0x00000006
				0x00000007
				0x00000006
				0x0000001e
				0x00000000
				0x0000000a
				0x0000000a
				0x00001c28
				0x00000000
				0x00000000
				0x00000000
				0x1049b898
				0xe00400b1
				0x00008000
				0x007fc008
				0x007fc008
				0x007fc008
				0x007fc008
				0x007fc008
				0x007fc008
				0x007fc008
				0x007fc008
				0x007fc008
				0x007fc008
				0x007fc008
				0x007fc008
				0x007fc008
				0x007fc008
				0x007fc008
				0x007fc008
				0x00000000
				0x00000000
				0x00000000
				0x00000000
				0x00000000
				0x00000000
				0x00000000
				0x00000000
				0x0001c000
				0x0001c000
				0x00000000
				0x0001c000
				0x0001c000
				0x00000000
				0x00000000
				0x00000000
				0x00000000
				0x00000000
				0x00000000
				0x00000000
				0x00000000
				0x00000000
				0x00000006
				0x00000006
				0x00000006
				0x00000006
				0x00000006
				0x00000006
				0x00000006
				0x00000006
				0x00000006
				0x00000006
				0x00000006
				0x00000006
				0x00000006
				0x00000006
				0x00000006
				0x00000006
				0x0000000a
				0x0000000a
				0x0000000a
				0x0000000a
				0x0000000a
				0x0000000a
				0x0000000a
				0x0000000a
				0x100002a0
				0x00000000
				0x00111111
				0x0120113d
				0x00000000
				0x00000000
				0x77ffc085
				0x00000202
				0x81f1f108
				0x07070004
				0x00000000
				0x016eeeee
				0x5d75d720
				0x00555555
				0x00555555
				0x5d75d700
				0x0606003f
				0x00000000
				0x00000000
				0x00020000
				0x00000128
				0x00cd000e
				0x00cd000e
				0x00000000
				0x00000004
				0x00004080
				0x800037ea
				0x00000011
				0x0e00000d
				0x80000040
				0x00000005
				0x00000006
				0x00000016
				0x0000000e
				0x0000000f
				0x00000002
				0x00000004
				0x0000000e
				0x00000002
				0x00000002
				0x00000006
				0x00000009
				0x09060202
				0x001a1016
				0x734e2a17
				0x70000f02
				0x001f0000
			>;
			nvidia,emc-burst-up-down-regs = <
			0x00000017
			0x000001bb
			0x006e0038
			0x006e0038
			0x006e003c
			0x006e0090
			0x006e0041
			0x006e0090
			0x006e0041
			0x00270049
			0x006e0080
			0x006e0004
			0x006e0004
			0x00080016
			0x0000006e
			0x006e0004
			0x006e0019
			0x006e0018
			0x006e0024
			0x006e001b
			0x0000006e
			0x00000036
			0x006e006e
			0x00000036
			0x006e006e
			0x00d400ff
			0x00510029
			0x006e006e
			0x006e006e
			0x006e0065
			0x006e001c
			>;
			nvidia,emc-zcal-cnt-long = <0x0000004c>;
			nvidia,emc-acal-interval = <0x001fffff>;
			nvidia,emc-ctt-term_ctrl = <0x00000802>;
			nvidia,emc-cfg = <0x73300000>;
			nvidia,emc-cfg-2 = <0x0000089d>;
			nvidia,emc-sel-dpd-ctrl = <0x00040000>;
			nvidia,emc-cfg-dig-dll = <0xe0040069>;
			nvidia,emc-bgbias-ctl0 = <0x00000000>;
			nvidia,emc-auto-cal-config2 = <0x00000000>;
			nvidia,emc-auto-cal-config3 = <0x00000000>;
			nvidia,emc-auto-cal-config = <0xa1430000>;
			nvidia,emc-mode-0 = <0x80000f15>;
			nvidia,emc-mode-1 = <0x80100002>;
			nvidia,emc-mode-2 = <0x80200020>;
			nvidia,emc-mode-4 = <0x00000000>;
			nvidia,emc-clock-latency-change = <1180>;
		};
	};
};
